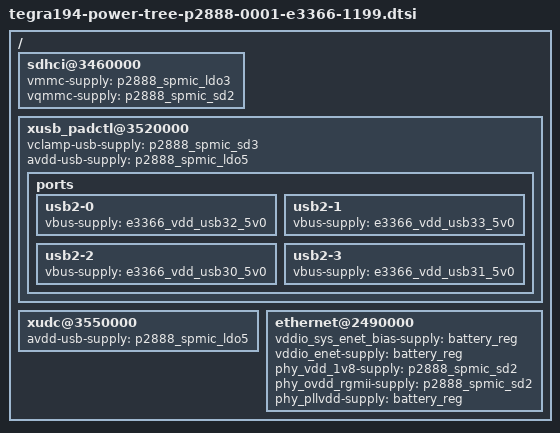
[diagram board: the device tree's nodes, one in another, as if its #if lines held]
/*
 * Copyright (c) 2019-2020, NVIDIA CORPORATION.  All rights reserved.
 *
 * This program is free software; you can redistribute it and/or modify it
 * under the terms and conditions of the GNU General Public License,
 * version 2, as published by the Free Software Foundation.
 *
 * This program is distributed in the hope it will be useful, but WITHOUT
 * ANY WARRANTY; without even the implied warranty of MERCHANTABILITY or
 * FITNESS FOR A PARTICULAR PURPOSE.  See the GNU General Public License for
 * more details.
 *
 * You should have received a copy of the GNU General Public License
 * along with this program.  If not, see <http://www.gnu.org/licenses/>.
 */

#include "tegra194-spmic-p2888-0001.dtsi"
#include "tegra194-fixed-regulator-p2888-0001.dtsi"
#include "tegra194-fixed-regulator-e3366-1199.dtsi"
/ {
	sdhci@3460000 {
		vmmc-supply = <&p2888_spmic_ldo3>;
		vqmmc-supply = <&p2888_spmic_sd2>;
	};
	xusb_padctl@3520000 {
#if TEGRA_XUSB_DT_VERSION >= DT_VERSION_3
		vclamp-usb-supply = <&p2888_spmic_sd3>;
		avdd-usb-supply = <&p2888_spmic_ldo5>;
#else
		pex_dvdd-supply = <&p2888_spmic_sd0>;
		pex_hvdd-supply = <&p2888_spmic_sd1>;
		pex_pll_hvdd-supply = <&p2888_spmic_sd1>;
		vclamp_usb-supply = <&p2888_spmic_sd3>;
		avdd_usb-supply = <&p2888_spmic_ldo5>;
		avdd_pll_nvhs_eutmip-supply = <&p2888_spmic_sd1>;
#endif

		ports {
			usb2-0 {
				vbus-supply = <&e3366_vdd_usb32_5v0>;
			};
			usb2-1 {
				vbus-supply = <&e3366_vdd_usb33_5v0>;
			};
			usb2-2 {
				vbus-supply = <&e3366_vdd_usb30_5v0>;
			};
			usb2-3 {
				vbus-supply = <&e3366_vdd_usb31_5v0>;
			};
		};
	};
	xudc@3550000 {
		avdd-usb-supply = <&p2888_spmic_ldo5>;
	};

	ethernet@2490000 {
		vddio_sys_enet_bias-supply = <&battery_reg>;
		vddio_enet-supply = <&battery_reg>;
		phy_vdd_1v8-supply = <&p2888_spmic_sd2>;
		phy_ovdd_rgmii-supply = <&p2888_spmic_sd2>;
		phy_pllvdd-supply = <&battery_reg>;
	};
};
